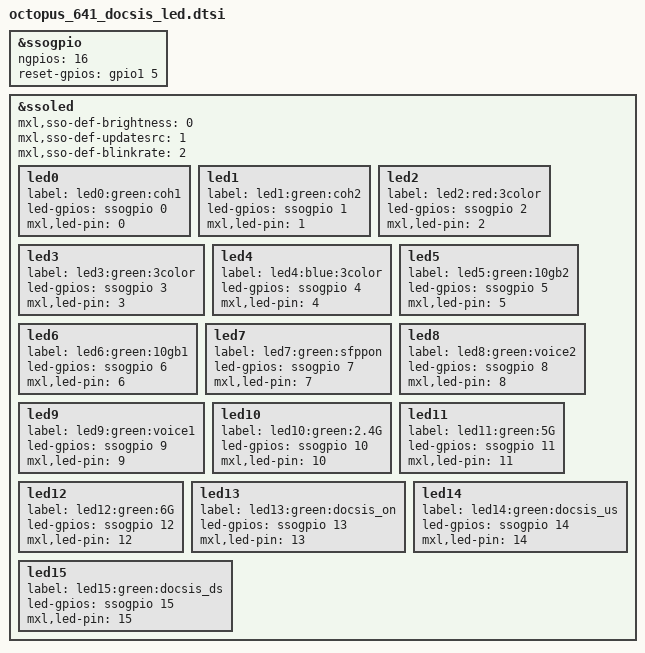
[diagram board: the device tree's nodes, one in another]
// SPDX-License-Identifier: GPL-2.0
/*
 * Copyright (C) 2023 MaxLinear, Inc.
 */

&ssogpio {
	status = "okay";
	ngpios = <16>;
	reset-gpios = <&gpio1 5 GPIO_ACTIVE_HIGH>;  /* gpio 37 */
};

&ssoled {
	status = "okay";
	mxl,sso-def-brightness = <0>;
	mxl,sso-def-updatesrc = <1>; /* 0 - manual, 1 - gptc 2 - fpid */
	mxl,sso-def-blinkrate = <2>;

	led0: led0 { /* COH1 */
		label = "led0:green:coh1";
		led-gpios = <&ssogpio 0 0>;
		mxl,led-pin = <0>;
	};

	led1: led1 { /* COH2 */
		label = "led1:green:coh2";
		led-gpios = <&ssogpio 1 0>;
		mxl,led-pin = <1>;
	};

	led2: led2 { /* 3COLOR */
		label = "led2:red:3color";
		led-gpios = <&ssogpio 2 0>;
		mxl,led-pin = <2>;
	};

	led3: led3 { /* 3COLOR */
		label = "led3:green:3color";
		led-gpios = <&ssogpio 3 0>;
		mxl,led-pin = <3>;
	};

	led4: led4 { /* 3COLOR */
		label = "led4:blue:3color";
		led-gpios = <&ssogpio 4 0>;
		mxl,led-pin = <4>;
	};

	led5: led5 { /* 10GB2 */
		label = "led5:green:10gb2";
		led-gpios = <&ssogpio 5 0>;
		mxl,led-pin = <5>;
	};

	led6: led6 { /* 10GB1 */
		label = "led6:green:10gb1";
		led-gpios = <&ssogpio 6 0>;
		mxl,led-pin = <6>;
	};

	led7: led7 { /* SFP PON */
		label = "led7:green:sfppon";
		led-gpios = <&ssogpio 7 0>;
		mxl,led-pin = <7>;
	};

	led8: led8 { /* Voice 2 */
		label = "led8:green:voice2";
		led-gpios = <&ssogpio 8 0>;
		mxl,led-pin = <8>;
	};

	led9: led9 { /* Voice 1 */
		label = "led9:green:voice1";
		led-gpios = <&ssogpio 9 0>;
		mxl,led-pin = <9>;
	};

	led10: led10 { /* 2.4GHz */
		label = "led10:green:2.4G";
		led-gpios = <&ssogpio 10 0>;
		mxl,led-pin = <10>;
	};

	led11: led11 { /* 5GHz */
		label = "led11:green:5G";
		led-gpios = <&ssogpio 11 0>;
		mxl,led-pin = <11>;
	};

	led12: led12 { /* 6 GHz */
		label = "led12:green:6G";
		led-gpios = <&ssogpio 12 0>;
		mxl,led-pin = <12>;
	};

	led13: led13 { /* DOCSIS ON */
		label = "led13:green:docsis_on";
		led-gpios = <&ssogpio 13 0>;
		mxl,led-pin = <13>;
	};

	led14: led14 { /* DOCSIS US */
		label = "led14:green:docsis_us";
		led-gpios = <&ssogpio 14 0>;
		mxl,led-pin = <14>;
	};

	led15: led15 { /* DOCSIS DS */
		label = "led15:green:docsis_ds";
		led-gpios = <&ssogpio 15 0>;
		mxl,led-pin = <15>;
	};
};
